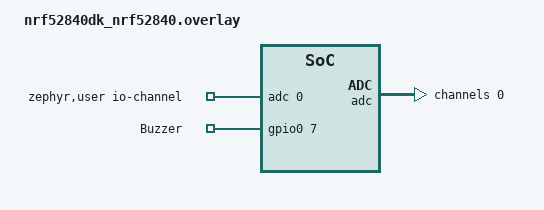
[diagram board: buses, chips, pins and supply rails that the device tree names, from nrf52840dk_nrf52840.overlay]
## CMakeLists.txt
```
# SPDX-License-Identifier: Apache-2.0

cmake_minimum_required(VERSION 3.20.0)

find_package(Zephyr REQUIRED HINTS $ENV{ZEPHYR_BASE})
project(hello_world)

target_sources(app PRIVATE src/main.c)

# Custom files and folders
target_sources(app PRIVATE
    src/buzzer.c
    src/battery.c
    src/ble/bluetoothle.c
    src/ble/gatt_bas.c
    src/ble/gatt_custom.c
)
```

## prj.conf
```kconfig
# Configure for stack size for threads
CONFIG_SYSTEM_WORKQUEUE_STACK_SIZE=3072
CONFIG_MAIN_STACK_SIZE=4096
CONFIG_ISR_STACK_SIZE=4096
CONFIG_BT_RX_STACK_SIZE=4096
CONFIG_BT_HCI_TX_STACK_SIZE=4096
CONFIG_HEAP_MEM_POOL_SIZE=4096
# Configure logger
CONFIG_LOG=y
CONFIG_LOG_BACKEND_RTT=n
CONFIG_LOG_BACKEND_UART=y


# Configure debugger
CONFIG_THREAD_NAME=y
CONFIG_DEBUG_THREAD_INFO=y
CONFIG_DEBUG_OPTIMIZATIONS=y
CONFIG_THREAD_ANALYZER=y
CONFIG_SEGGER_SYSTEMVIEW=y
CONFIG_USE_SEGGER_RTT=y
CONFIG_TRACING=y
CONFIG_TRACING_BACKEND_RAM=y
CONFIG_ASSERT=y
CONFIG_RESET_ON_FATAL_ERROR=n
CONFIG_DEBUG=y

# Configure Bluetooth
CONFIG_BT=y
CONFIG_BT_PERIPHERAL=y
CONFIG_BT_DEVICE_NAME="BLE_BUZZER"
CONFIG_BT_MAX_CONN=1
CONFIG_BT_LL_SOFTDEVICE=y

CONFIG_ADC=y

# Enable mcumgr.
CONFIG_MCUMGR=y

# Ensure an MCUboot-compatible binary is generated.
CONFIG_BOOTLOADER_MCUBOOT=y

# Enable flash operations.
CONFIG_FLASH=y

# Required by the `taskstat` command.
CONFIG_THREAD_MONITOR=y

# Enable statistics and statistic names.
CONFIG_STATS=y
CONFIG_STATS_NAMES=y

# Enable most core commands.
CONFIG_MCUMGR_CMD_IMG_MGMT=y
CONFIG_MCUMGR_CMD_OS_MGMT=y
CONFIG_MCUMGR_CMD_STAT_MGMT=y

# Allow for large Bluetooth data packets.
CONFIG_BT_L2CAP_TX_MTU=252
CONFIG_BT_BUF_ACL_RX_SIZE=256

# Enable the Bluetooth (unauthenticated) and shell mcumgr transports.
CONFIG_MCUMGR_SMP_BT=y
CONFIG_MCUMGR_SMP_BT_AUTHEN=n
CONFIG_MCUMGR_SMP_SHELL=y
CONFIG_NCS_SAMPLE_MCUMGR_BT_OTA_DFU=y
```

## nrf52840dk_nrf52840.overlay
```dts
/{
    zephyr,user {
        io-channels = <&adc 0>;
    };

    leds {
        compatible = "gpio-leds";
        buzzer: buzzer_pin {
            gpios = <&gpio0 7 GPIO_ACTIVE_HIGH>;
            label = "Buzzer";
        };
    };
};
&adc {
	#address-cells = <1>;
	#size-cells = <0>;
	status="okay";

	channel@0 {
		reg = <0>;
		zephyr,gain = "ADC_GAIN_1_6";
		zephyr,reference = "ADC_REF_INTERNAL";
		zephyr,acquisition-time = <ADC_ACQ_TIME_DEFAULT>;
		zephyr,input-positive = <NRF_SAADC_VDD>;
		zephyr,resolution = <14>;
		zephyr,oversampling = <8>;
	};
};
```

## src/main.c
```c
/*
 * Copyright (c) 2012-2014 Wind River Systems, Inc.
 *
 * SPDX-License-Identifier: Apache-2.0
 */

#include <zephyr/kernel.h>
#include "ble/bluetoothle.h"
#include "buzzer.h"
#include "battery.h"

void main(void)
{
	int err;
	printk("Hello World! %s\n", CONFIG_BOARD);
	battery_init();
	buzzer_init();

	ble_init();	

	err = smp_bt_register();

	if (err) {
		printk("SMP BT register failed (err: %d)", err);
	}
}
```

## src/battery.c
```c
/*******************************************************************************
* Title                 :    
* Filename              :   battery.c
* Author                :   thuantm5
* Origin Date           :   2023/05/01
* Version               :   0.0.0
* Compiler              :   nRF connect SDK v2.3
* Target                :   nRF52
* Notes                 :   None
*******************************************************************************/

/*************** MODULE REVISION LOG ******************************************
*
*    Date       Software Version	Initials	Description
*  2023/05/01       0.0.0	         thuantm5      Module Created.
*
*******************************************************************************/

/** \file battery.c
 *  \brief This module contains the
 */
/******************************************************************************
* Includes
*******************************************************************************/
#include "battery.h"
#include <zephyr/drivers/adc.h>
/******************************************************************************
* Module Preprocessor Constants
*******************************************************************************/
#define MODULE_NAME			battery
#define MODULE_LOG_LEVEL	LOG_LEVEL_DBG
LOG_MODULE_REGISTER(MODULE_NAME, MODULE_LOG_LEVEL);

/******************************************************************************
* Module Preprocessor Macros
*******************************************************************************/
#if !DT_NODE_EXISTS(DT_PATH(zephyr_user)) || \
	!DT_NODE_HAS_PROP(DT_PATH(zephyr_user), io_channels)
#error "No suitable devicetree overlay specified"
#endif

#define DT_SPEC_AND_COMMA(node_id, prop, idx) \
	ADC_DT_SPEC_GET_BY_IDX(node_id, idx),

/* Data of ADC io-channels specified in devicetree. */
static const struct adc_dt_spec adc_channels[] = {
	DT_FOREACH_PROP_ELEM(DT_PATH(zephyr_user), io_channels,DT_SPEC_AND_COMMA)
};
/******************************************************************************
* Module Typedefs
*******************************************************************************/

/******************************************************************************
* Module Variable Definitions
*******************************************************************************/
static uint16_t raw_adc_mv;
struct adc_sequence sequence = {
    .buffer = &raw_adc_mv,
    /* buffer size in bytes, not number of samples */
    .buffer_size = sizeof(raw_adc_mv),
};
/******************************************************************************
* Function Prototypes
*******************************************************************************/

/******************************************************************************
* Function Definitions
*******************************************************************************/
void battery_init()
{
    int err;
    LOG_INF("Battery init");
    if (!device_is_ready(adc_channels[0].dev)) {
		LOG_ERR("ADC controller device not ready, error: %d\n", err);
		return;
	}
	err = adc_channel_setup_dt(&adc_channels[0]);
	if (err < 0) {
		LOG_ERR("Could not setup channel #%d (%d)\n", 0, err);
		return;
	}
	adc_sequence_init_dt(&adc_channels[0], &sequence);
    LOG_INF("Battery init successfully \n");

}

uint8_t battery_level(void) {
	int err;
	int32_t val_mv;
    uint8_t batt_percent = 0; 

	err = adc_read(adc_channels[0].dev, &sequence);
	if (err < 0) {
		LOG_ERR("Could not read (%d)\n", err);
		return batt_percent; 
	}

	val_mv = raw_adc_mv;
	err = adc_raw_to_millivolts_dt(&adc_channels[0], &val_mv);
	if (err < 0) {
		LOG_ERR(" (value in mV not available)\n");
		return batt_percent; 
	}
    LOG_INF("Battery value: %d mV \n", val_mv);

	if (val_mv >= BATTERY_FULL_MV) 
    {
		batt_percent = 100; 
	} 
    else if (val_mv <= BATTERY_DEAD_MV) 
    {
		batt_percent = 0;
	} 
    else if (val_mv >= BATTERY_HALF_MV) 
    {
		batt_percent = (val_mv - BATTERY_HALF_MV) * 50 / (BATTERY_FULL_MV - BATTERY_HALF_MV) + 50;
	} 
    else if (val_mv >= BATTERY_QUARTER_MV)
    {
		batt_percent = (val_mv - BATTERY_QUARTER_MV) * 25 / (BATTERY_HALF_MV - BATTERY_QUARTER_MV) + 25;
	} 
    else 
    {
		batt_percent = (val_mv - BATTERY_DEAD_MV) * 25 / (BATTERY_QUARTER_MV - BATTERY_DEAD_MV) + 0;
	}
	return batt_percent; 
}
```

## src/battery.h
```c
/****************************************************************************
* Title                 :    header file
* Filename              :   battery.h
* Author                :   thuantm5
* Origin Date           :   2023/05/01
* Version               :   v0.0.0
* Compiler              :   nRF connect SDK v2.3
* Target                :   nRF52
* Notes                 :   None
*****************************************************************************/

/*************** INTERFACE CHANGE LIST **************************************
*
*    Date    	Software Version    Initials   	Description
*  2023/05/01    v0.0.0         	thuantm5      Interface Created.
*
*****************************************************************************/

/** \file battery.h
 *  \brief This module contains .
 *
 *  This is the header file for 
 */
#ifndef BATTERY_H_
#define BATTERY_H_

/******************************************************************************
* Includes
*******************************************************************************/
#include <zephyr/kernel.h>
#include <zephyr/logging/log.h>
#include <zephyr/drivers/gpio.h>
#include <zephyr/devicetree.h>


/******************************************************************************
* Preprocessor Constants
*******************************************************************************/
// Voltage to level curve for a coin cell 3V battery. 
#define BATTERY_FULL_MV         2950
#define BATTERY_HALF_MV         2900
#define BATTERY_QUARTER_MV      2800
#define BATTERY_DEAD_MV         2300

/******************************************************************************
* Configuration Constants
*******************************************************************************/


/******************************************************************************
* Macros
*******************************************************************************/


/******************************************************************************
* Typedefs
*******************************************************************************/


/******************************************************************************
* Variables
*******************************************************************************/

/******************************************************************************
* Function Prototypes
*******************************************************************************/
void battery_init();
uint8_t battery_level(void);
#endif // BATTERY_H_

/*** End of File **************************************************************/
```

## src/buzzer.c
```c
/*******************************************************************************
* Title                 :   
* Filename              :   buzzer.c
* Author                :   thuantm96
* Origin Date           :   2023/05/01
* Version               :   0.0.0
* Compiler              :   nRF connect SDK v2.3
* Target                :   nRF52
* Notes                 :   None
*******************************************************************************/

/*************** MODULE REVISION LOG ******************************************
*
*    Date       Software Version	Initials	Description
*  2023/05/01       0.0.0	         thuantm96      Module Created.
*
*******************************************************************************/

/** \file buzzer.c
 *  \brief This module contains the
 */
/******************************************************************************
* Includes
*******************************************************************************/
#include "buzzer.h"

/******************************************************************************
* Module Preprocessor Constants
*******************************************************************************/
#define MODULE_NAME			buzzer
#define MODULE_LOG_LEVEL	LOG_LEVEL_INF
LOG_MODULE_REGISTER(MODULE_NAME, MODULE_LOG_LEVEL);

/******************************************************************************
* Module Preprocessor Macros
*******************************************************************************/

/******************************************************************************
* Module Typedefs
*******************************************************************************/

/******************************************************************************
* Module Variable Definitions
*******************************************************************************/
static struct gpio_dt_spec buzzer_dt = GPIO_DT_SPEC_GET(DT_NODELABEL(buzzer), gpios);


uint8_t buzzer_state = 0;
/******************************************************************************
* Function Prototypes
*******************************************************************************/

/******************************************************************************
* Function Definitions
*******************************************************************************/
void buzzer_init()
{
    int ret;
	if (!device_is_ready(buzzer_dt.port)) {
		LOG_ERR("Buzzer pin device not ready");
	}

	ret = gpio_pin_configure_dt(&buzzer_dt, GPIO_OUTPUT_INACTIVE);
	if (ret < 0) {
		LOG_ERR("Failed to config Buzzer pin with err: %d", ret);
	}
    buzzer_state = 0;
	LOG_INF("Buzzer pin init succesfully");
}

void buzzer_on()
{
    int ret;
    ret = gpio_pin_set_dt(&buzzer_dt, 1);
    if (ret < 0) {
        LOG_ERR("Failed to turn on Buzzer pin with err: %d", ret);
        return;
    }
    buzzer_state = 1;
}

void buzzer_off()
{
    int ret;
    ret = gpio_pin_set_dt(&buzzer_dt, 0);
    if (ret < 0) {
        LOG_ERR("Failed to turn off Buzzer pin with err: %d", ret);
        return;
    }
    buzzer_state = 0;

}
```

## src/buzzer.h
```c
/****************************************************************************
* Title                 :   header file
* Filename              :   buzzer.h
* Author                :   thuantm96
* Origin Date           :   2023/05/01
* Version               :   v0.0.0
* Compiler              :   nRF connect SDK v2.3
* Target                :   nRF52
* Notes                 :   None
*****************************************************************************/

/*************** INTERFACE CHANGE LIST **************************************
*
*    Date    	Software Version    Initials   	Description
*  2023/05/01    v0.0.0         	thuantm96      Interface Created.
*
*****************************************************************************/

/** \file buzzer.h
 *  \brief This module contains .
 *
 *  This is the header file for 
 */
#ifndef BUZZER_H_
#define BUZZER_H_

/******************************************************************************
* Includes
*******************************************************************************/
#include <zephyr/kernel.h>
#include <zephyr/logging/log.h>
#include <zephyr/drivers/gpio.h>
#include <zephyr/devicetree.h>

/******************************************************************************
* Preprocessor Constants
*******************************************************************************/


/******************************************************************************
* Configuration Constants
*******************************************************************************/
#define BUZZER_OFF_TIMEOUT                      5000 //in miliseconds

/******************************************************************************
* Macros
*******************************************************************************/


/******************************************************************************
* Typedefs
*******************************************************************************/


/******************************************************************************
* Variables
*******************************************************************************/
extern uint8_t buzzer_state;


/******************************************************************************
* Function Prototypes
*******************************************************************************/
void buzzer_init();
void buzzer_on();
void buzzer_off();
#endif // BUZZER_H_

/*** End of File **************************************************************/
```
